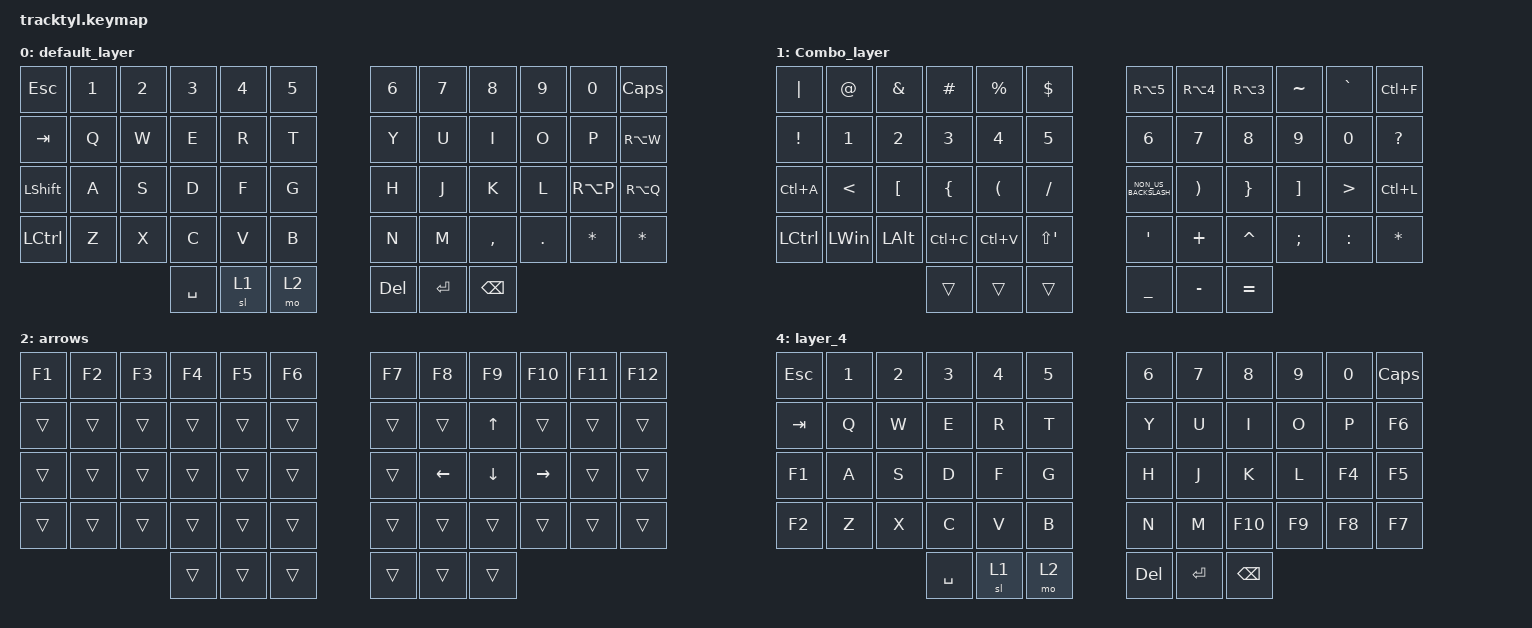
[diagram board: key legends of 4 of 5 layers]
#include <behaviors/mouse_key_press.dtsi>
#include <behaviors/mouse_move.dtsi>
#include <behaviors.dtsi>
#include <dt-bindings/zmk/keys.h>
#include <dt-bindings/zmk/mouse.h>

#define DEFAULT 0
#define Combo_layer 1
#define arrows 2
#define scroll 3
#define sniper 4

/ {
    trackball_listener {
        compatible = "zmk,input-behavior-listener";
        device = <&vtrackball>;
        layers = <0>;
        evt-type = <INPUT_EV_REL>;
        x-input-code = <INPUT_REL_X>;
        y-input-code = <INPUT_REL_Y>;
        //scale-multiplier = <5>;
        scale-multiplier = <3>;
        //scale-divisor = <1.5>;
    };

    trackball_listener2 {
        compatible = "zmk,input-behavior-listener";
        device = <&vtrackball2>;
        layers = <0>;
        evt-type = <INPUT_EV_REL>;
        x-input-code = <INPUT_REL_X>;
        y-input-code = <INPUT_REL_Y>;
        //scale-multiplier = <1>;
        scale-multiplier = <2>;
        //scale-divisor = <5>;
    };

    trackball_scroll_listener {
        compatible = "zmk,input-behavior-listener";
        device = <&vtrackball>;
        layers = <3>;
        y-invert;
        evt-type = <INPUT_EV_REL>;
        x-input-code = <INPUT_REL_MISC>;
        y-input-code = <INPUT_REL_WHEEL>;
        bindings = <&ib_wheel_scaler 1 25>;
    };

    trackball_scroll_listener2 {
        compatible = "zmk,input-behavior-listener";
        device = <&vtrackball2>;
        layers = <3>;
        y-invert;
        evt-type = <INPUT_EV_REL>;
        x-input-code = <INPUT_REL_MISC>;
        y-input-code = <INPUT_REL_WHEEL>;
        bindings = <&ib_wheel_scaler 1 25>;
    };

    trackball_snipe_listener {
        compatible = "zmk,input-behavior-listener";
        device = <&vtrackball>;
        layers = <4>;
        evt-type = <INPUT_EV_REL>;
        x-input-code = <INPUT_REL_X>;
        y-input-code = <INPUT_REL_Y>;
        scale-multiplier = <3>;
        //scale-divisor = <4>;
    };

    trackball_snipe_listener2 {
        compatible = "zmk,input-behavior-listener";
        device = <&vtrackball2>;
        layers = <4>;
        evt-type = <INPUT_EV_REL>;
        x-input-code = <INPUT_REL_X>;
        y-input-code = <INPUT_REL_Y>;
        scale-multiplier = <2>;
        //scale-divisor = <4>;
    };

    /* adjust cooldown waiting period for mouse key layer (MSK) after activated */

    ib_tog_layer: ib_tog_layer {
        compatible = "zmk,input-behavior-tog-layer";
        #binding-cells = <1>;
        time-to-live-ms = <1000>;
    };

    /* define a resolution down scaler only for INPUT_REL_WHEEL */

    ib_wheel_scaler: ib_wheel_scaler {
        compatible = "zmk,input-behavior-scaler";
        #binding-cells = <2>;
        evt-type = <INPUT_EV_REL>;
        input-code = <INPUT_REL_WHEEL>;
    };

    combos {
        compatible = "zmk,combos";

        Leftclick {
            bindings = <&mkp LCLK>;
            key-positions = <31 43>;
        };

        rightclick {
            bindings = <&mkp RCLK>;
            key-positions = <33 45>;
        };

        back {
            bindings = <&mkp MB4>;
            key-positions = <43 44>;
        };

        forward {
            bindings = <&mkp MB5>;
            key-positions = <45 44>;
        };

        scroll {
            bindings = <&mo 3>;
            key-positions = <30 31>;
        };

        newtab {
            bindings = <&kp LC(T)>;
            key-positions = <9 21>;
        };

        oldtab {
            bindings = <&kp LC(LS(T))>;
            key-positions = <7 19>;
        };

        closetab {
            bindings = <&kp LC(W)>;
            key-positions = <8 20>;
        };

        tableft {
            bindings = <&kp LC(LS(TAB))>;
            key-positions = <7 8>;
        };

        righttab {
            bindings = <&kp LC(TAB)>;
            key-positions = <9 8>;
        };

        alttabback {
            bindings = <&kp LS(TAB)>;
            key-positions = <2 1>;
        };

        alttabright {
            bindings = <&kp LC(LA(TAB))>;
            key-positions = <3 4>;
        };

        shift {
            bindings = <&sk LEFT_SHIFT>;
            key-positions = <34 46>;
        };

        paste {
            bindings = <&kp LC(V)>;
            key-positions = <40 28>;
        };

        copy {
            bindings = <&kp LC(C)>;
            key-positions = <39 27>;
        };

        cut {
            bindings = <&kp LC(X)>;
            key-positions = <26 38>;
        };

        undo {
            bindings = <&kp LC(Z)>;
            key-positions = <37 25>;
        };

        redo {
            bindings = <&kp LC(Y)>;
            key-positions = <25 13>;
        };

        searchbar {
            bindings = <&kp LC(L)>;
            key-positions = <22 10>;
        };

        uparrow {
            bindings = <&kp UP_ARROW>;
            key-positions = <20 32>;
        };

        downarrow {
            bindings = <&kp DOWN>;
            key-positions = <32 44>;
        };

        leftarow {
            bindings = <&kp LEFT_ARROW>;
            key-positions = <19 31>;
        };

        rightarrow {
            bindings = <&kp RIGHT>;
            key-positions = <21 33>;
        };

        alttabenter {
            bindings = <&kp ENTER>;
            key-positions = <3 2>;
        };

        layer2 {
            bindings = <&sl 1>;
            key-positions = <28 29>;
        };

        middleclick {
            bindings = <&mkp MCLK>;
            key-positions = <43 42>;
        };

        gamelayertoggle {
            bindings = <&tog 4>;
            key-positions = <0 1>;
        };
    };

    keymap {
        compatible = "zmk,keymap";

        /*
     * Base Layer: DEFAULT1
     *
     * ,------,----------------------------------.                ,----------------------------------.------.
     * |  esc |   1  |   2  |   3  |   4  |   5  |                |   6  |   7  |   8  |   9  |   0  |   0  |
     * ,------,----------------------------------.                ,----------------------------------.------.
     * |  tab |   Q  |   W  |   E  |   R  |   T  |                |   Y  |   U  |   I  |   O  |   P  |   å  |
     * |------|------+------+------+------+------|                |------+------+------+------+------|------|
     * | caps |   A  |   S  |  D   |   F  |   G  |                |   H  |   J  |   K  |   L  |  ö   |  ä   |
     * |------|------+------+------+------+------|                |------+------+------+------+------|------|
     * |shift |   Z  |   X  |   C  |   V  |   B  |                |   N  |   M  | ,  < | . >  | /  ? | /  ? |
     * `------`-------------+------+------+------+                +------+------+------+-------------'------'
     *                      | alt  | ctrl | tab  |                | enter| esc  | del  |
     *                      |      |      | shift|                | NUMS | ARWS |      |
     *                      ----------------------                --------------'------'
     */

        default_layer {
            bindings = <
&kp ESCAPE        &kp NUMBER_1  &kp NUMBER_2  &kp NUMBER_3  &kp NUMBER_4  &kp N5         &kp NUMBER_6  &kp N7  &kp N8     &kp N9   &kp N0     &kp CLCK
&kp TAB           &kp Q         &kp W         &kp E         &kp R         &kp T          &kp Y         &kp U   &kp I      &kp O    &kp P      &kp RA(W)
&kp LEFT_SHIFT    &kp A         &kp S         &kp D         &kp F         &kp G          &kp H         &kp J   &kp K      &kp L    &kp RA(P)  &kp RA(Q)
&kp LEFT_CONTROL  &kp Z         &kp X         &kp C         &kp V         &kp B          &kp N         &kp M   &kp COMMA  &kp DOT  &kp STAR   &kp ASTERISK
&kp SPACE         &sl 1         &mo 2         &kp DELETE    &kp ENTER     &kp BACKSPACE
            >;
        };

        Combo_layer {
            bindings = <
&kp PIPE   &kp AT         &kp AMPS          &kp HASH        &kp PERCENT           &kp DOLLAR            &kp RA(NUMBER_5)      &kp RA(NUMBER_4)       &kp RA(NUMBER_3)  &kp TILDE          &kp GRAVE         &kp LC(F)
&kp EXCL   &kp N1         &kp N2            &kp N3          &kp N4                &kp N5                &kp N6                &kp N7                 &kp N8            &kp N9             &kp N0            &kp QUESTION
&kp LC(A)  &kp LESS_THAN  &kp LEFT_BRACKET  &kp LEFT_BRACE  &kp LEFT_PARENTHESIS  &kp SLASH             &kp NON_US_BACKSLASH  &kp RIGHT_PARENTHESIS  &kp RIGHT_BRACE   &kp RIGHT_BRACKET  &kp GREATER_THAN  &kp LC(L)
&kp LCTRL  &kp LEFT_WIN   &kp LEFT_ALT      &kp LC(C)       &kp LC(V)             &kp LS(SINGLE_QUOTE)  &kp SINGLE_QUOTE      &kp PLUS               &kp CARET         &kp SEMICOLON      &kp COLON         &kp STAR
&trans     &trans         &trans            &kp UNDER       &kp MINUS             &kp EQUAL
            >;
        };

        arrows {
            bindings = <
&kp F1  &kp F2  &kp F3  &kp F4  &kp F5  &kp F6  &kp F7  &kp F8          &kp F9          &kp F10          &kp F11  &kp F12
&trans  &trans  &trans  &trans  &trans  &trans  &trans  &trans          &kp UP_ARROW    &trans           &trans   &trans
&trans  &trans  &trans  &trans  &trans  &trans  &trans  &kp LEFT_ARROW  &kp DOWN_ARROW  &kp RIGHT_ARROW  &trans   &trans
&trans  &trans  &trans  &trans  &trans  &trans  &trans  &trans          &trans          &trans           &trans   &trans
&trans  &trans  &trans  &trans  &trans  &trans
            >;
        };

        scroll {
            bindings = <
&trans  &trans  &trans  &trans  &trans  &trans  &trans  &trans  &trans  &trans  &trans  &trans
&trans  &trans  &trans  &trans  &trans  &trans  &trans  &trans  &trans  &trans  &trans  &trans
&trans  &trans  &trans  &trans  &trans  &trans  &trans  &trans  &trans  &trans  &trans  &trans
&trans  &trans  &trans  &trans  &trans  &trans  &trans  &trans  &trans  &trans  &trans  &trans
&trans  &trans  &trans  &trans  &trans  &trans  &trans  &trans  &trans
            >;
        };

        layer_4 {
            bindings = <
&kp ESCAPE  &kp NUMBER_1  &kp NUMBER_2  &kp NUMBER_3  &kp NUMBER_4  &kp N5         &kp NUMBER_6  &kp N7  &kp N8   &kp N9  &kp N0  &kp CLCK
&kp TAB     &kp Q         &kp W         &kp E         &kp R         &kp T          &kp Y         &kp U   &kp I    &kp O   &kp P   &kp F6
&kp F1      &kp A         &kp S         &kp D         &kp F         &kp G          &kp H         &kp J   &kp K    &kp L   &kp F4  &kp F5
&kp F2      &kp Z         &kp X         &kp C         &kp V         &kp B          &kp N         &kp M   &kp F10  &kp F9  &kp F8  &kp F7
&kp SPACE      &sl 1         &mo 2         &kp DELETE    &kp ENTER     &kp BACKSPACE
            >;
        };
    };
};
